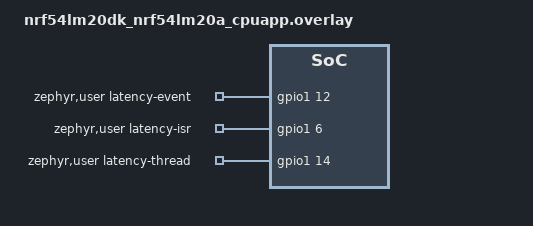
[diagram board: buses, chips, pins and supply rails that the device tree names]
/*
 * Copyright (c) 2026 Nordic Semiconductor ASA
 *
 * SPDX-License-Identifier: LicenseRef-Nordic-5-Clause
 */

/ {
	zephyr,user {
		latency-event-gpios = <&gpio1 12 GPIO_ACTIVE_HIGH>;
		latency-isr-gpios = <&gpio1 6 GPIO_ACTIVE_HIGH>;
		latency-thread-gpios = <&gpio1 14 GPIO_ACTIVE_HIGH>;
	};
};
